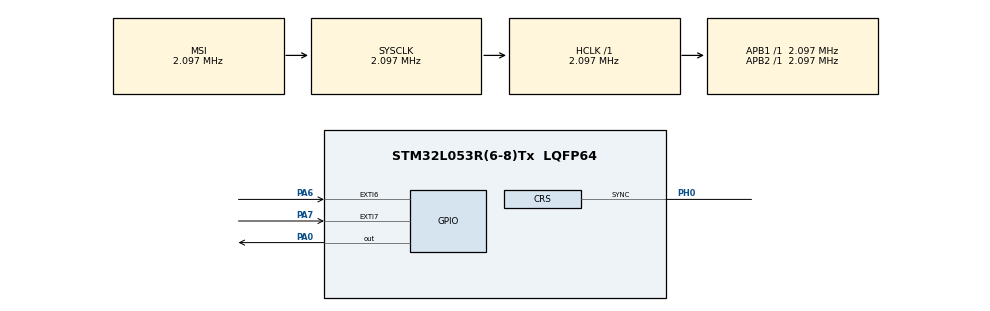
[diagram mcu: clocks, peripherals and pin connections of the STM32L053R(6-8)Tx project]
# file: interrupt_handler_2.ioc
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Mcu.Family=STM32L0
Mcu.Name=STM32L053R(6-8)Tx
Mcu.Package=LQFP64
NVIC.EXTI4_15_IRQn=true\:0\:0\:false\:false\:true\:true\:true\:true
PA0.Signal=GPIO_Output
PA6.Signal=GPXTI6
PA7.Signal=GPXTI7
PH0-OSC_IN.Mode=CRS SYNC Source GPIO
PH0-OSC_IN.Signal=CRS_SYNC
ProjectManager.HeapSize=0x200
ProjectManager.StackSize=0x400
ProjectManager.TargetToolchain=STM32CubeIDE
RCC.AHBFreq_Value=2097000
RCC.APB1Freq_Value=2097000
RCC.APB1TimFreq_Value=2097000
RCC.APB2Freq_Value=2097000
RCC.APB2TimFreq_Value=2097000
RCC.HSE_VALUE=8000000
RCC.HSI16_VALUE=16000000
RCC.HSI48_VALUE=48000000
RCC.HSI_VALUE=16000000
RCC.LSE_VALUE=32768
RCC.MSI_VALUE=2097000
RCC.SYSCLKFreq_VALUE=2097000
RCC.VCOOutputFreq_Value=48000000
board=custom

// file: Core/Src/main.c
/* USER CODE BEGIN Header */
/**
  ******************************************************************************
  * @file           : main.c
  * @brief          : Main program body
  ******************************************************************************
  * @attention
  *
  * Copyright (c) 2023 STMicroelectronics.
  * All rights reserved.
  *
  * This software is licensed under terms that can be found in the LICENSE file
  * in the root directory of this software component.
  * If no LICENSE file comes with this software, it is provided AS-IS.
  *
  ******************************************************************************
  */
/* USER CODE END Header */
#include "main.h"

void SystemClock_Config(void);
static void MX_GPIO_Init(void);

/* USER CODE BEGIN 0 */

void HAL_GPIO_EXTI_Callback(uint16_t GPIO_Pin)
{
	/* Prevent unused argument(s) compilation warning */
	if(GPIO_Pin == GPIO_PIN_6) {
		HAL_GPIO_WritePin(GPIOA, GPIO_PIN_0, GPIO_PIN_SET);
	} else if (GPIO_Pin == GPIO_PIN_7) {
		HAL_GPIO_WritePin(GPIOA, GPIO_PIN_0, GPIO_PIN_RESET);
	}
  /* NOTE: This function Should not be modified, when the callback is needed,
		   the HAL_GPIO_EXTI_Callback could be implemented in the user file
   */
}
/* USER CODE END 0 */

int main(void)
{
  /* USER CODE BEGIN 1 */
	HAL_GPIO_WritePin(GPIOA, GPIO_PIN_0, GPIO_PIN_SET);
  /* USER CODE END 1 */

  /* MCU Configuration--------------------------------------------------------*/

  /* Reset of all peripherals, Initializes the Flash interface and the Systick. */
  HAL_Init();

  /* Configure the system clock */
  SystemClock_Config();

  /* Initialize all configured peripherals */
  MX_GPIO_Init();

  /* Infinite loop */
  while (1)
  {

  }
}

void SystemClock_Config(void)
{
  RCC_OscInitTypeDef RCC_OscInitStruct = {0};
  RCC_ClkInitTypeDef RCC_ClkInitStruct = {0};
  RCC_CRSInitTypeDef RCC_CRSInitStruct = {0};

  /** Configure the main internal regulator output voltage
  */
  __HAL_PWR_VOLTAGESCALING_CONFIG(PWR_REGULATOR_VOLTAGE_SCALE1);

  /** Initializes the RCC Oscillators according to the specified parameters
  * in the RCC_OscInitTypeDef structure.
  */
  RCC_OscInitStruct.OscillatorType = RCC_OSCILLATORTYPE_MSI;
  RCC_OscInitStruct.MSIState = RCC_MSI_ON;
  RCC_OscInitStruct.MSICalibrationValue = 0;
  RCC_OscInitStruct.MSIClockRange = RCC_MSIRANGE_5;
  RCC_OscInitStruct.PLL.PLLState = RCC_PLL_NONE;
  if (HAL_RCC_OscConfig(&RCC_OscInitStruct) != HAL_OK)
  {
    Error_Handler();
  }

  /** Initializes the CPU, AHB and APB buses clocks
  */
  RCC_ClkInitStruct.ClockType = RCC_CLOCKTYPE_HCLK|RCC_CLOCKTYPE_SYSCLK
                              |RCC_CLOCKTYPE_PCLK1|RCC_CLOCKTYPE_PCLK2;
  RCC_ClkInitStruct.SYSCLKSource = RCC_SYSCLKSOURCE_MSI;
  RCC_ClkInitStruct.AHBCLKDivider = RCC_SYSCLK_DIV1;
  RCC_ClkInitStruct.APB1CLKDivider = RCC_HCLK_DIV1;
  RCC_ClkInitStruct.APB2CLKDivider = RCC_HCLK_DIV1;

  if (HAL_RCC_ClockConfig(&RCC_ClkInitStruct, FLASH_LATENCY_0) != HAL_OK)
  {
    Error_Handler();
  }

  /** Enable the SYSCFG APB clock
  */
  __HAL_RCC_CRS_CLK_ENABLE();

  /** Configures CRS
  */
  RCC_CRSInitStruct.Prescaler = RCC_CRS_SYNC_DIV1;
  RCC_CRSInitStruct.Source = RCC_CRS_SYNC_SOURCE_GPIO;
  RCC_CRSInitStruct.Polarity = RCC_CRS_SYNC_POLARITY_RISING;
  RCC_CRSInitStruct.ReloadValue = __HAL_RCC_CRS_RELOADVALUE_CALCULATE(48000000,1);
  RCC_CRSInitStruct.ErrorLimitValue = 34;
  RCC_CRSInitStruct.HSI48CalibrationValue = 32;

  HAL_RCCEx_CRSConfig(&RCC_CRSInitStruct);
}

static void MX_GPIO_Init(void)
{
  GPIO_InitTypeDef GPIO_InitStruct = {0};

  /* GPIO Ports Clock Enable */
  __HAL_RCC_GPIOH_CLK_ENABLE();
  __HAL_RCC_GPIOA_CLK_ENABLE();

  /*Configure GPIO pin Output Level */
  HAL_GPIO_WritePin(GPIOA, GPIO_PIN_0, GPIO_PIN_RESET);

  /*Configure GPIO pin : PH0 */
  GPIO_InitStruct.Pin = GPIO_PIN_0;
  GPIO_InitStruct.Mode = GPIO_MODE_AF_PP;
  GPIO_InitStruct.Pull = GPIO_NOPULL;
  GPIO_InitStruct.Speed = GPIO_SPEED_FREQ_LOW;
  GPIO_InitStruct.Alternate = GPIO_AF0_USB;
  HAL_GPIO_Init(GPIOH, &GPIO_InitStruct);

  /*Configure GPIO pin : PA0 */
  GPIO_InitStruct.Pin = GPIO_PIN_0;
  GPIO_InitStruct.Mode = GPIO_MODE_OUTPUT_PP;
  GPIO_InitStruct.Pull = GPIO_NOPULL;
  GPIO_InitStruct.Speed = GPIO_SPEED_FREQ_LOW;
  HAL_GPIO_Init(GPIOA, &GPIO_InitStruct);

  /*Configure GPIO pins : PA6 PA7 */
  GPIO_InitStruct.Pin = GPIO_PIN_6|GPIO_PIN_7;
  GPIO_InitStruct.Mode = GPIO_MODE_IT_RISING;
  GPIO_InitStruct.Pull = GPIO_NOPULL;
  HAL_GPIO_Init(GPIOA, &GPIO_InitStruct);

  /* EXTI interrupt init*/
  HAL_NVIC_SetPriority(EXTI4_15_IRQn, 0, 0);
  HAL_NVIC_EnableIRQ(EXTI4_15_IRQn);

}

void Error_Handler(void)
{
  __disable_irq();
  while (1)
  {
  }
}
